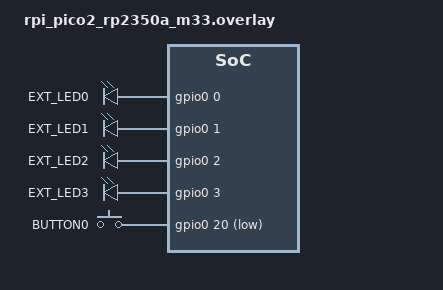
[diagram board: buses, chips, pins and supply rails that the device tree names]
/ {
    aliases {
        /* External LEDs */
        led0 = &ext_led0;
        led1 = &ext_led1;
        led2 = &ext_led2;
        led3 = &ext_led3;

        /* Button on GP20 */
        sw0  = &btn0;
    };

    leds {
        compatible = "gpio-leds";

        ext_led0: led_0 {
            gpios = <&gpio0 0 GPIO_ACTIVE_HIGH>;  /* GP0 */
            label = "EXT_LED0";
        };

        ext_led1: led_1 {
            gpios = <&gpio0 1 GPIO_ACTIVE_HIGH>;  /* GP1 */
            label = "EXT_LED1";
        };

        ext_led2: led_2 {
            gpios = <&gpio0 2 GPIO_ACTIVE_HIGH>;  /* GP2 */
            label = "EXT_LED2";
        };

        ext_led3: led_3 {
            gpios = <&gpio0 3 GPIO_ACTIVE_HIGH>;  /* GP3 */
            label = "EXT_LED3";
        };
    };

    gpio_keys {
        compatible = "gpio-keys";

        btn0: button_0 {
            gpios = <&gpio0 20 (GPIO_PULL_UP | GPIO_ACTIVE_LOW)>; /* GP20 */
            label = "BUTTON0";
        };
    };
};
